# MB9BF36xx register map
File version: 1.0
CPU: 
Registers are 8-bit, read-write, reset 0x0 unless marked. A register's access mark holds for its fields unless they carry their own. Offsets are from the block's base; [hi:lo] are bit positions; {n}, {i} and the like mark numbered series.

## INTREQ — peripheral INTREQ
Base 0x40031000
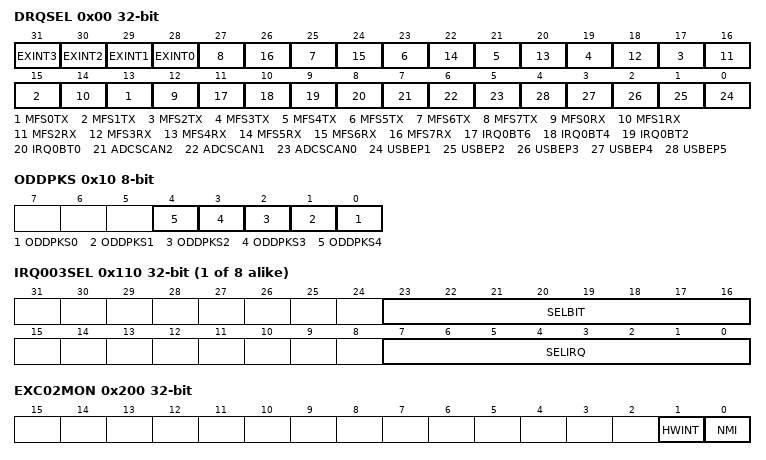
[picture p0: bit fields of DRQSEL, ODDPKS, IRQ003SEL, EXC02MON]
0x00 DRQSEL 32-bit
  [n+28] EXINT{n} (n=0..3), [2n+13] MFS{n}TX (n=0..7), [2n+12] MFS{n}RX (n=0..7), [11] IRQ0BT6, [10] IRQ0BT4, [9] IRQ0BT2, [8] IRQ0BT0, [7] ADCSCAN2, [6] ADCSCAN1, [5] ADCSCAN0, [n-1] USBEP{n} (n=1..5)
0x10 ODDPKS
  [n] ODDPKS{n} (n=0..4)
{0x104+4i} IRQ{i:03}SEL 32-bit (i=3..10)
  [23:16] SELBIT, [7:0] SELIRQ
0x200 EXC02MON 32-bit ro
  [1] HWINT, [0] NMI
0x204 IRQ000MON 32-bit ro
  [0] FCSINT
0x208 IRQ001MON 32-bit ro
  [0] SWWDTINT
0x20C IRQ002MON 32-bit ro
  [0] LVDINT
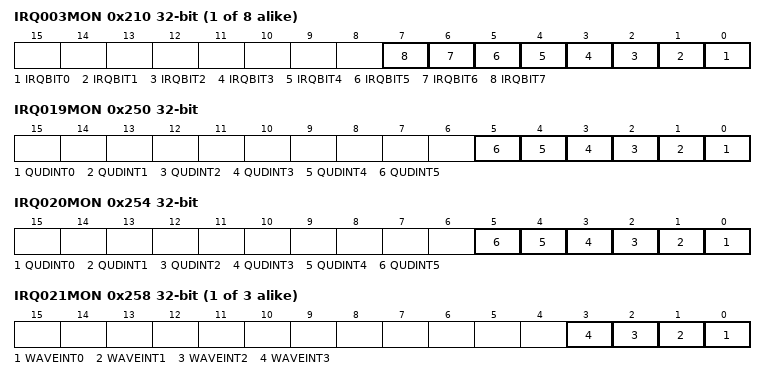
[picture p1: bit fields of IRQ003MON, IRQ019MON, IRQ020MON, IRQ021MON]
{0x204+4i} IRQ{i:03}MON 32-bit ro (i=3..10)
  [n] IRQBIT{n} (n=0..7)
{0x204+4i} IRQ{i:03}MON 32-bit ro (i=11..18)
  [0] EXTINT
0x250 IRQ019MON 32-bit ro
  [n] QUDINT{n} (n=0..5)
0x254 IRQ020MON 32-bit ro
  [n] QUDINT{n} (n=0..5)
{0x204+4i} IRQ{i:03}MON 32-bit ro (i=21..23)
  [n] WAVEINT{n} (n=0..3)
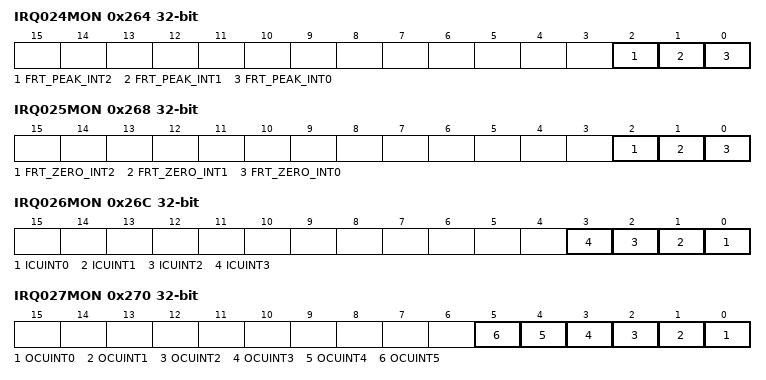
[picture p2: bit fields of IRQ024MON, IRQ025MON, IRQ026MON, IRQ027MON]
0x264 IRQ024MON 32-bit ro
  [2] FRT_PEAK_INT2, [1] FRT_PEAK_INT1, [0] FRT_PEAK_INT0
0x268 IRQ025MON 32-bit ro
  [2] FRT_ZERO_INT2, [1] FRT_ZERO_INT1, [0] FRT_ZERO_INT0
0x26C IRQ026MON 32-bit ro
  [n] ICUINT{n} (n=0..3)
0x270 IRQ027MON 32-bit ro
  [n] OCUINT{n} (n=0..5)
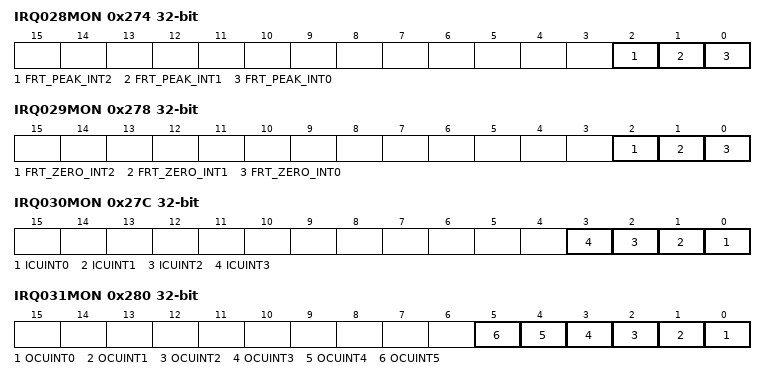
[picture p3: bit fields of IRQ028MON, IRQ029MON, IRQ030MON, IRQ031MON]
0x274 IRQ028MON 32-bit ro
  [2] FRT_PEAK_INT2, [1] FRT_PEAK_INT1, [0] FRT_PEAK_INT0
0x278 IRQ029MON 32-bit ro
  [2] FRT_ZERO_INT2, [1] FRT_ZERO_INT1, [0] FRT_ZERO_INT0
0x27C IRQ030MON 32-bit ro
  [n] ICUINT{n} (n=0..3)
0x280 IRQ031MON 32-bit ro
  [n] OCUINT{n} (n=0..5)
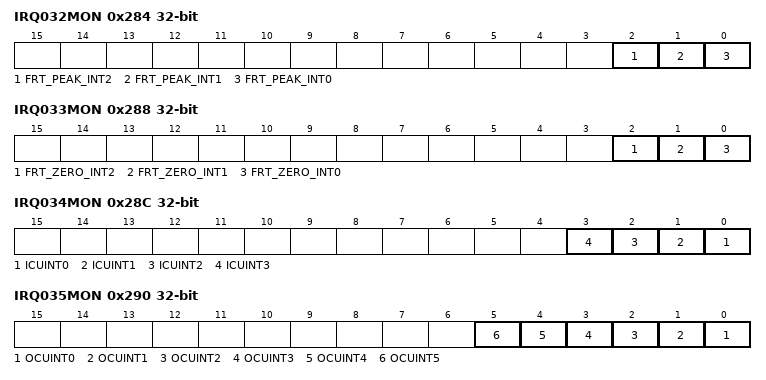
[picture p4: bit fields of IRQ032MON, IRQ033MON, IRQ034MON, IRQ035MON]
0x284 IRQ032MON 32-bit ro
  [2] FRT_PEAK_INT2, [1] FRT_PEAK_INT1, [0] FRT_PEAK_INT0
0x288 IRQ033MON 32-bit ro
  [2] FRT_ZERO_INT2, [1] FRT_ZERO_INT1, [0] FRT_ZERO_INT0
0x28C IRQ034MON 32-bit ro
  [n] ICUINT{n} (n=0..3)
0x290 IRQ035MON 32-bit ro
  [n] OCUINT{n} (n=0..5)
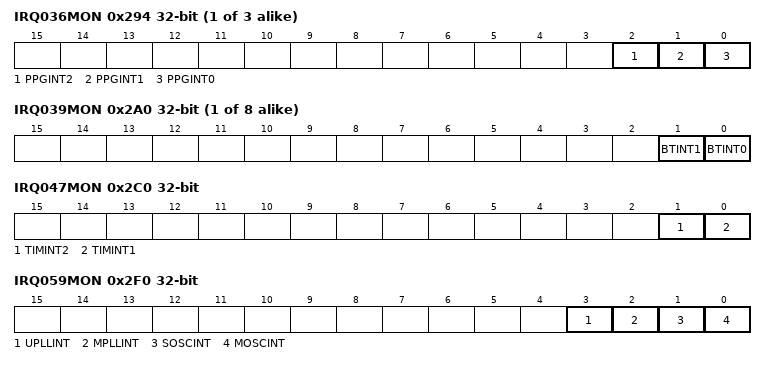
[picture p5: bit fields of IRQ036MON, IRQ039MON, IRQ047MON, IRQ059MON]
{0x204+4i} IRQ{i:03}MON 32-bit ro (i=36..38)
  [2] PPGINT2, [1] PPGINT1, [0] PPGINT0
{0x204+4i} IRQ{i:03}MON 32-bit ro (i=39..46)
  [1] BTINT1, [0] BTINT0
0x2C0 IRQ047MON 32-bit ro
  [1] TIMINT2, [0] TIMINT1
0x2C4 IRQ048MON 32-bit ro
  [0] WCINT
0x2C8 IRQ049MON 32-bit ro
  [0] BMEMCS
0x2CC IRQ050MON 32-bit ro
  [0] RTCINT
{0x204+4i} IRQ{i:03}MON 32-bit ro (i=51..58)
  [0] EXTINT
0x2F0 IRQ059MON 32-bit ro
  [3] UPLLINT, [2] MPLLINT, [1] SOSCINT, [0] MOSCINT
0x2F4 IRQ060MON 32-bit ro
  [0] MFSRINT
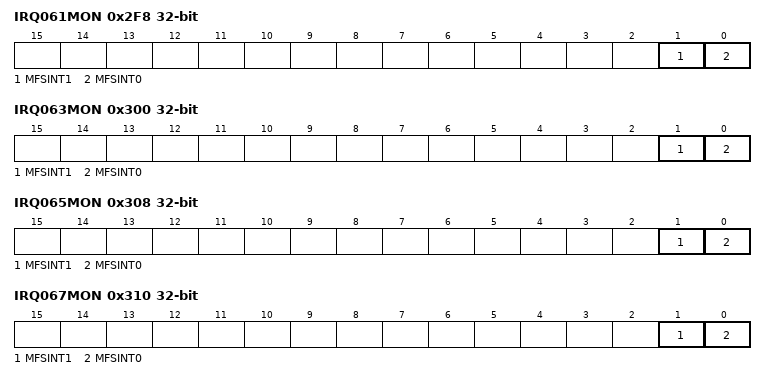
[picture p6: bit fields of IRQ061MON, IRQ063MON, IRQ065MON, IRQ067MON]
0x2F8 IRQ061MON 32-bit ro
  [1] MFSINT1, [0] MFSINT0
0x2FC IRQ062MON 32-bit ro
  [0] MFSRINT
0x300 IRQ063MON 32-bit ro
  [1] MFSINT1, [0] MFSINT0
0x304 IRQ064MON 32-bit ro
  [0] MFSRINT
0x308 IRQ065MON 32-bit ro
  [1] MFSINT1, [0] MFSINT0
0x30C IRQ066MON 32-bit ro
  [0] MFSRINT
0x310 IRQ067MON 32-bit ro
  [1] MFSINT1, [0] MFSINT0
0x314 IRQ068MON 32-bit ro
  [0] MFSRINT
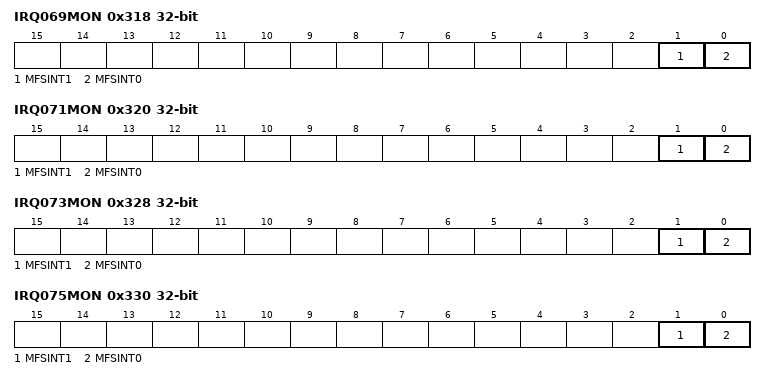
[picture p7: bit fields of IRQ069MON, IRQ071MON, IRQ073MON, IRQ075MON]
0x318 IRQ069MON 32-bit ro
  [1] MFSINT1, [0] MFSINT0
0x31C IRQ070MON 32-bit ro
  [0] MFSRINT
0x320 IRQ071MON 32-bit ro
  [1] MFSINT1, [0] MFSINT0
0x324 IRQ072MON 32-bit ro
  [0] MFSRINT
0x328 IRQ073MON 32-bit ro
  [1] MFSINT1, [0] MFSINT0
0x32C IRQ074MON 32-bit ro
  [0] MFSRINT
0x330 IRQ075MON 32-bit ro
  [1] MFSINT1, [0] MFSINT0
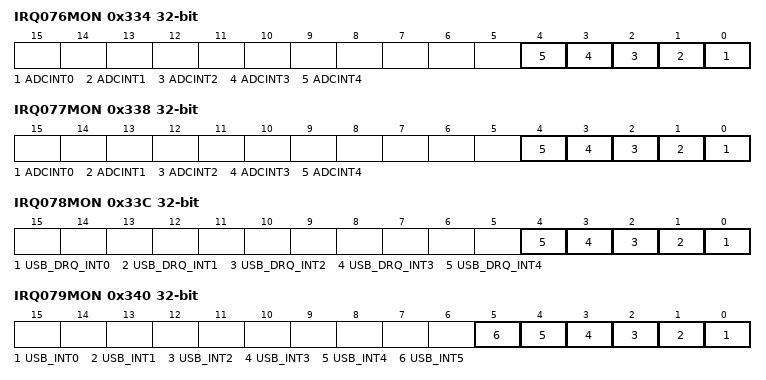
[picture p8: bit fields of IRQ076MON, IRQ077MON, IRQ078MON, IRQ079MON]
0x334 IRQ076MON 32-bit ro
  [n] ADCINT{n} (n=0..4)
0x338 IRQ077MON 32-bit ro
  [n] ADCINT{n} (n=0..4)
0x33C IRQ078MON 32-bit ro
  [n] USB_DRQ_INT{n} (n=0..4)
0x340 IRQ079MON 32-bit ro
  [n] USB_INT{n} (n=0..5)
0x344 IRQ080MON 32-bit ro
  [0] CANINT
0x348 IRQ081MON 32-bit ro
  [0] CANINT
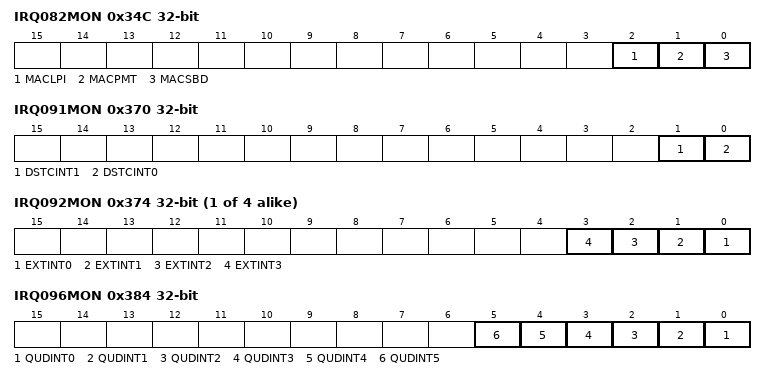
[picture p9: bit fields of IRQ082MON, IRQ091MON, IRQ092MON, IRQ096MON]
0x34C IRQ082MON 32-bit ro
  [2] MACLPI, [1] MACPMT, [0] MACSBD
{0x204+4i} IRQ{i:03}MON 32-bit ro (i=83..90)
  [0] DMACINT
0x370 IRQ091MON 32-bit ro
  [1] DSTCINT1, [0] DSTCINT0
{0x204+4i} IRQ{i:03}MON 32-bit ro (i=92..95)
  [n] EXTINT{n} (n=0..3)
0x384 IRQ096MON 32-bit ro
  [n] QUDINT{n} (n=0..5)
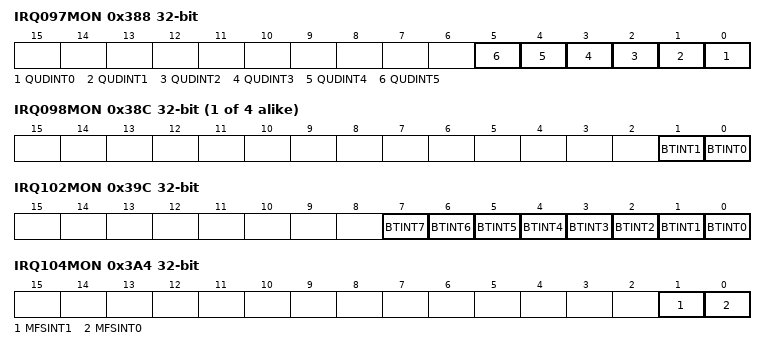
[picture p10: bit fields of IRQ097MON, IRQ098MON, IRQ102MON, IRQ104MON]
0x388 IRQ097MON 32-bit ro
  [n] QUDINT{n} (n=0..5)
{0x204+4i} IRQ{i:03}MON 32-bit ro (i=98..101)
  [1] BTINT1, [0] BTINT0
0x39C IRQ102MON 32-bit ro
  [n] BTINT{n} (n=0..7)
0x3A0 IRQ103MON 32-bit ro
  [0] MFSRINT
0x3A4 IRQ104MON 32-bit ro
  [1] MFSINT1, [0] MFSINT0
0x3A8 IRQ105MON 32-bit ro
  [0] MFSRINT
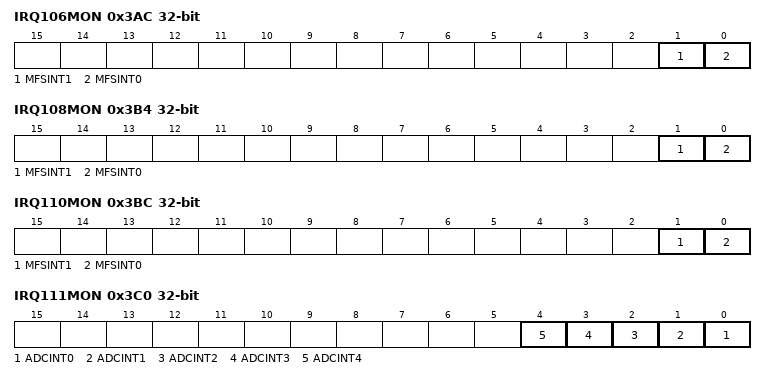
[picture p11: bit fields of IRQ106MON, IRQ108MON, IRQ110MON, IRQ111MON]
0x3AC IRQ106MON 32-bit ro
  [1] MFSINT1, [0] MFSINT0
0x3B0 IRQ107MON 32-bit ro
  [0] MFSRINT
0x3B4 IRQ108MON 32-bit ro
  [1] MFSINT1, [0] MFSINT0
0x3B8 IRQ109MON 32-bit ro
  [0] MFSRINT
0x3BC IRQ110MON 32-bit ro
  [1] MFSINT1, [0] MFSINT0
0x3C0 IRQ111MON 32-bit ro
  [n] ADCINT{n} (n=0..4)
0x3C4 IRQ112MON 32-bit ro reset not defined
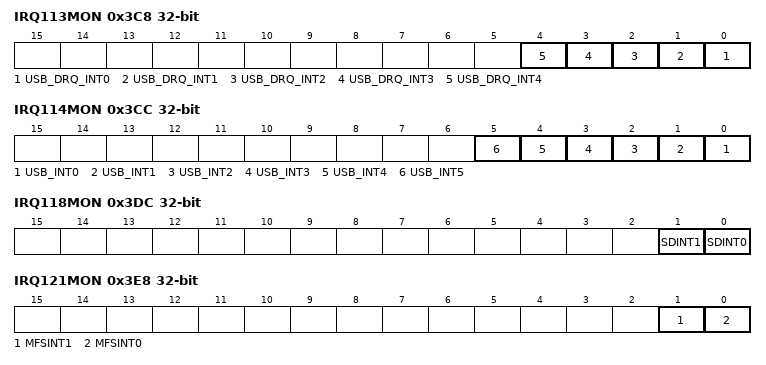
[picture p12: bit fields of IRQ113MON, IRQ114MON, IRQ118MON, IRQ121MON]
0x3C8 IRQ113MON 32-bit ro
  [n] USB_DRQ_INT{n} (n=0..4)
0x3CC IRQ114MON 32-bit ro
  [n] USB_INT{n} (n=0..5)
{0x204+4i} IRQ{i}MON 32-bit ro reset not defined (i=115..117)
0x3DC IRQ118MON 32-bit ro
  [1] SDINT1, [0] SDINT0
0x3E0 IRQ119MON 32-bit ro
  [0] FLINT
0x3E4 IRQ120MON 32-bit ro
  [0] MFSRINT
0x3E8 IRQ121MON 32-bit ro
  [1] MFSINT1, [0] MFSINT0
0x3EC IRQ122MON 32-bit ro
  [0] MFSRINT
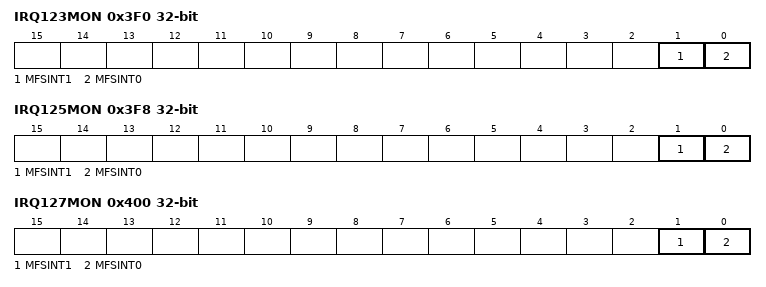
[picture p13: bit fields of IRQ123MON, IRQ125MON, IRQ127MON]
0x3F0 IRQ123MON 32-bit ro
  [1] MFSINT1, [0] MFSINT0
0x3F4 IRQ124MON 32-bit ro
  [0] MFSRINT
0x3F8 IRQ125MON 32-bit ro
  [1] MFSINT1, [0] MFSINT0
0x3FC IRQ126MON 32-bit ro
  [0] MFSRINT
0x400 IRQ127MON 32-bit ro
  [1] MFSINT1, [0] MFSINT0
